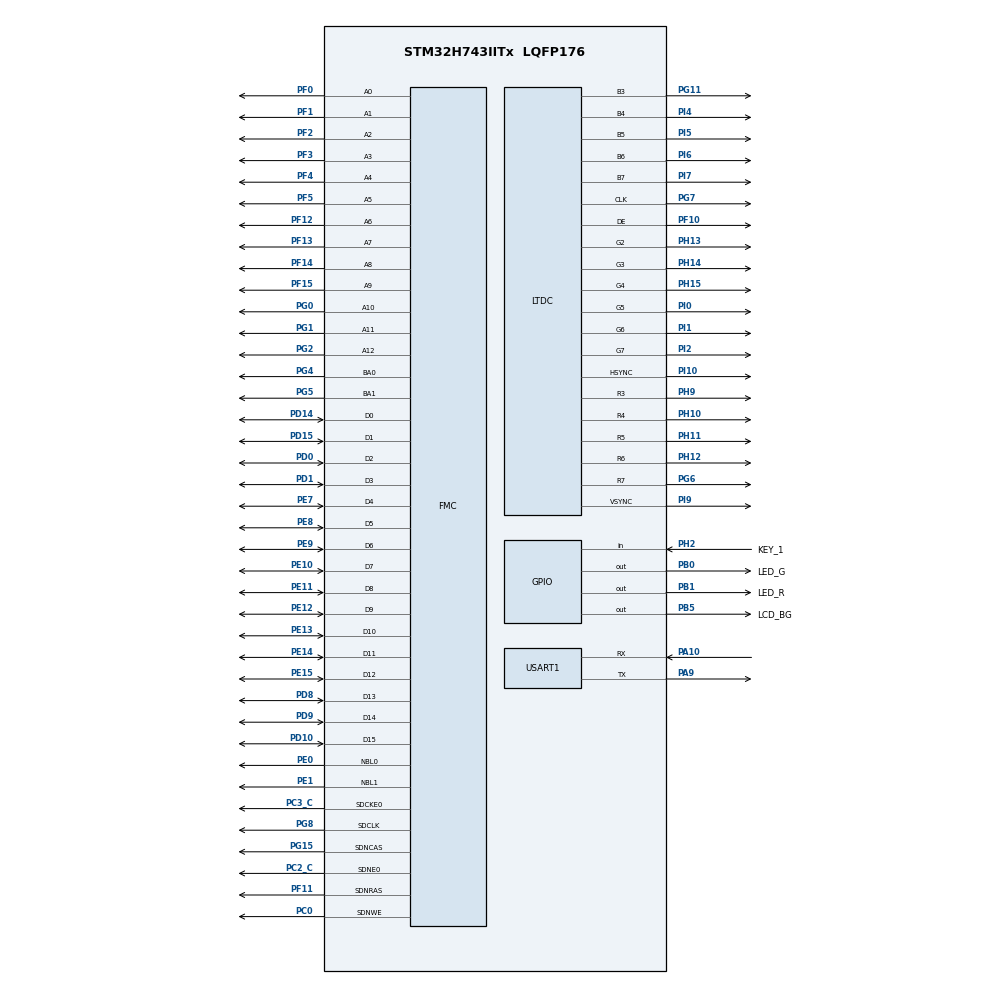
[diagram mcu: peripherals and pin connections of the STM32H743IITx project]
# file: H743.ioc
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CORTEX_M7.CPU_DCache=Enabled
CORTEX_M7.CPU_ICache=Enabled
DMA2D.ColorMode=DMA2D_OUTPUT_RGB565
FMC.CASLatency1=FMC_SDRAM_CAS_LATENCY_2
FMC.ColumnBitsNumber1=FMC_SDRAM_COLUMN_BITS_NUM_9
FMC.ExitSelfRefreshDelay1=8
FMC.LoadToActiveDelay1=2
FMC.RCDDelay1=2
FMC.RPDelay1=2
FMC.RPDelay2=2
FMC.ReadBurst1=FMC_SDRAM_RBURST_ENABLE
FMC.ReadBurst2=FMC_SDRAM_RBURST_ENABLE
FMC.ReadPipeDelay1=FMC_SDRAM_RPIPE_DELAY_0
FMC.RowCycleDelay1=7
FMC.RowCycleDelay2=7
FMC.SDClockPeriod1=FMC_SDRAM_CLOCK_PERIOD_2
FMC.SDClockPeriod2=FMC_SDRAM_CLOCK_PERIOD_2
FMC.SelfRefreshTime1=7
FMC.WriteRecoveryTime1=5
FREERTOS.BinarySemaphores01=ScreenFlushSemaphore,Dynamic,NULL,Depleted
FREERTOS.Queues01=LEDQueue,16,LEDMessage*,0,Dynamic,NULL,NULL;CommandQueue,16,uint8_t,0,Dynamic,NULL,NULL
FREERTOS.Tasks01=UITask,24,2048,StartUITask,As weak,NULL,Dynamic,NULL,NULL;KeyScanTask,40,128,StartKeyScanTask,As external,NULL,Dynamic,NULL,NULL;LEDTask,24,128,StartLEDTask,As external,NULL,Dynamic,NULL,NULL
FREERTOS.configCHECK_FOR_STACK_OVERFLOW=2
FREERTOS.configGENERATE_RUN_TIME_STATS=1
FREERTOS.configRECORD_STACK_HIGH_ADDRESS=1
FREERTOS.configTOTAL_HEAP_SIZE=32768
FREERTOS.configUSE_STATS_FORMATTING_FUNCTIONS=1
FREERTOS.configUSE_TICK_HOOK=1
LTDC.ActiveH=480
LTDC.ActiveW=800
LTDC.Alpha0_L0=255
LTDC.Alpha_L0=255
LTDC.Blue_L0=255
LTDC.FBStartAdress_L0=0xC0000000
LTDC.HBP=46
LTDC.HFP=210
LTDC.HSync=1
LTDC.ImageHeight_L0=480
LTDC.ImageWidth_L0=800
LTDC.Layers=0
LTDC.PixelFormat_L0=LTDC_PIXEL_FORMAT_RGB565
LTDC.VBP=23
LTDC.VFP=22
LTDC.VSync=1
LTDC.WindowX1_L0=800
LTDC.WindowY1_L0=480
Mcu.Family=STM32H7
Mcu.Name=STM32H743IITx
Mcu.Package=LQFP176
NVIC.DMA2D_IRQn=true\:7\:0\:true\:false\:true\:true\:true\:true\:true
NVIC.LTDC_IRQn=true\:7\:0\:true\:false\:true\:true\:true\:true\:true
NVIC.PriorityGroup=NVIC_PRIORITYGROUP_4
NVIC.TIM6_DAC_IRQn=true\:0\:0\:true\:false\:true\:false\:true\:true\:true
NVIC.TimeBase=TIM6_DAC_IRQn
NVIC.TimeBaseIP=TIM6
NVIC.USART1_IRQn=true\:5\:0\:false\:false\:true\:true\:true\:true\:true
PA10.GPIO_Speed=GPIO_SPEED_FREQ_VERY_HIGH
PA10.Mode=Asynchronous
PA10.Signal=USART1_RX
PA13\ (JTMS/SWDIO).Mode=Serial_Wire
PA13\ (JTMS/SWDIO).Signal=DEBUG_JTMS-SWDIO
PA14\ (JTCK/SWCLK).Mode=Serial_Wire
PA14\ (JTCK/SWCLK).Signal=DEBUG_JTCK-SWCLK
PA9.GPIO_Speed=GPIO_SPEED_FREQ_VERY_HIGH
PA9.Mode=Asynchronous
PA9.Signal=USART1_TX
PB0.GPIO_Label=LED_G
PB0.GPIO_Speed=GPIO_SPEED_FREQ_VERY_HIGH
PB0.Signal=GPIO_Output
PB1.GPIO_Label=LED_R
PB1.GPIO_Speed=GPIO_SPEED_FREQ_VERY_HIGH
PB1.Signal=GPIO_Output
PB5.GPIO_Label=LCD_BG
PB5.GPIO_ModeDefaultOutputPP=GPIO_MODE_OUTPUT_PP
PB5.GPIO_Speed=GPIO_SPEED_FREQ_VERY_HIGH
PB5.PinState=GPIO_PIN_SET
PB5.Signal=GPIO_Output
PC0.Signal=FMC_SDNWE
PC14-OSC32_IN\ (OSC32_IN).Mode=LSE-External-Oscillator
PC14-OSC32_IN\ (OSC32_IN).Signal=RCC_OSC32_IN
PC15-OSC32_OUT\ (OSC32_OUT).Mode=LSE-External-Oscillator
PC15-OSC32_OUT\ (OSC32_OUT).Signal=RCC_OSC32_OUT
PC2_C.Mode=SdramChipSelect1_1
PC2_C.Signal=FMC_SDNE0
PC3_C.Mode=SdramChipSelect1_1
PC3_C.Signal=FMC_SDCKE0
PD0.Signal=FMC_D2_DA2
PD1.Signal=FMC_D3_DA3
PD10.Signal=FMC_D15_DA15
PD14.Signal=FMC_D0_DA0
PD15.Signal=FMC_D1_DA1
PD8.Signal=FMC_D13_DA13
PD9.Signal=FMC_D14_DA14
PE0.Signal=FMC_NBL0
PE1.Signal=FMC_NBL1
PE10.Signal=FMC_D7_DA7
PE11.Signal=FMC_D8_DA8
PE12.Signal=FMC_D9_DA9
PE13.Signal=FMC_D10_DA10
PE14.Signal=FMC_D11_DA11
PE15.Signal=FMC_D12_DA12
PE7.Signal=FMC_D4_DA4
PE8.Signal=FMC_D5_DA5
PE9.Signal=FMC_D6_DA6
PF0.Signal=FMC_A0
PF1.Signal=FMC_A1
PF10.GPIO_Speed=GPIO_SPEED_FREQ_VERY_HIGH
PF10.Mode=RGB565
PF10.Signal=LTDC_DE
PF11.Signal=FMC_SDNRAS
PF12.Signal=FMC_A6
PF13.Signal=FMC_A7
PF14.Signal=FMC_A8
PF15.Signal=FMC_A9
PF2.Signal=FMC_A2
PF3.Signal=FMC_A3
PF4.Signal=FMC_A4
PF5.Signal=FMC_A5
PG0.Signal=FMC_A10
PG1.Signal=FMC_A11
PG11.GPIO_Speed=GPIO_SPEED_FREQ_VERY_HIGH
PG11.Mode=RGB565
PG11.Signal=LTDC_B3
PG15.Signal=FMC_SDNCAS
PG2.Signal=FMC_A12
PG4.Signal=FMC_A14_BA0
PG5.Signal=FMC_A15_BA1
PG6.GPIO_Speed=GPIO_SPEED_FREQ_VERY_HIGH
PG6.Mode=RGB565
PG6.Signal=LTDC_R7
PG7.GPIO_Speed=GPIO_SPEED_FREQ_VERY_HIGH
PG7.Mode=RGB565
PG7.Signal=LTDC_CLK
PG8.Signal=FMC_SDCLK
PH0-OSC_IN\ (PH0).Mode=HSE-External-Oscillator
PH0-OSC_IN\ (PH0).Signal=RCC_OSC_IN
PH1-OSC_OUT\ (PH1).Mode=HSE-External-Oscillator
PH1-OSC_OUT\ (PH1).Signal=RCC_OSC_OUT
PH10.GPIO_Speed=GPIO_SPEED_FREQ_VERY_HIGH
PH10.Mode=RGB565
PH10.Signal=LTDC_R4
PH11.GPIO_Speed=GPIO_SPEED_FREQ_VERY_HIGH
PH11.Mode=RGB565
PH11.Signal=LTDC_R5
PH12.GPIO_Speed=GPIO_SPEED_FREQ_VERY_HIGH
PH12.Mode=RGB565
PH12.Signal=LTDC_R6
PH13.GPIO_Speed=GPIO_SPEED_FREQ_VERY_HIGH
PH13.Mode=RGB565
PH13.Signal=LTDC_G2
PH14.GPIO_Speed=GPIO_SPEED_FREQ_VERY_HIGH
PH14.Mode=RGB565
PH14.Signal=LTDC_G3
PH15.GPIO_Speed=GPIO_SPEED_FREQ_VERY_HIGH
PH15.Mode=RGB565
PH15.Signal=LTDC_G4
PH2.GPIO_Label=KEY_1
PH2.GPIO_PuPd=GPIO_PULLUP
PH2.Signal=GPIO_Input
PH9.GPIO_Speed=GPIO_SPEED_FREQ_VERY_HIGH
PH9.Mode=RGB565
PH9.Signal=LTDC_R3
PI0.GPIO_Speed=GPIO_SPEED_FREQ_VERY_HIGH
PI0.Mode=RGB565
PI0.Signal=LTDC_G5
PI1.GPIO_Speed=GPIO_SPEED_FREQ_VERY_HIGH
PI1.Mode=RGB565
PI1.Signal=LTDC_G6
PI10.GPIO_Speed=GPIO_SPEED_FREQ_VERY_HIGH
PI10.Mode=RGB565
PI10.Signal=LTDC_HSYNC
PI2.GPIO_Speed=GPIO_SPEED_FREQ_VERY_HIGH
PI2.Mode=RGB565
PI2.Signal=LTDC_G7
PI4.GPIO_Speed=GPIO_SPEED_FREQ_VERY_HIGH
PI4.Mode=RGB565
PI4.Signal=LTDC_B4
PI5.GPIO_Speed=GPIO_SPEED_FREQ_VERY_HIGH
PI5.Mode=RGB565
PI5.Signal=LTDC_B5
PI6.GPIO_Speed=GPIO_SPEED_FREQ_VERY_HIGH
PI6.Mode=RGB565
PI6.Signal=LTDC_B6
PI7.GPIO_Speed=GPIO_SPEED_FREQ_VERY_HIGH
PI7.Mode=RGB565
PI7.Signal=LTDC_B7
PI9.GPIO_Speed=GPIO_SPEED_FREQ_VERY_HIGH
PI9.Mode=RGB565
PI9.Signal=LTDC_VSYNC
ProjectManager.HeapSize=0x2000
ProjectManager.StackSize=0x2000
ProjectManager.TargetToolchain=CMake
RCC.ADCFreq_Value=110000000
RCC.APB1Freq_Value=120000000
RCC.APB2Freq_Value=120000000
RCC.APB3Freq_Value=120000000
RCC.APB4Freq_Value=120000000
RCC.CortexFreq_Value=480000000
RCC.D1PPRE=RCC_APB3_DIV2
RCC.D2PPRE1=RCC_APB1_DIV2
RCC.D2PPRE2=RCC_APB2_DIV2
RCC.D3PPRE=RCC_APB4_DIV2
RCC.DIVM1=5
RCC.DIVM2=25
RCC.DIVM3=25
RCC.DIVN1=192
RCC.DIVN2=220
RCC.DIVN3=300
RCC.DIVR2=1
RCC.DIVR3=9
RCC.FMCCLockSelection=RCC_FMCCLKSOURCE_PLL2
RCC.HCLKFreq_Value=240000000
RCC.HPRE=RCC_HCLK_DIV2
RCC.PLLFRACN=0
RCC.PLLSourceVirtual=RCC_PLLSOURCE_HSE
RCC.SYSCLKFreq_VALUE=480000000
RCC.SYSCLKSource=RCC_SYSCLKSOURCE_PLLCLK
RCC.USBFreq_Value=480000000
SH.FMC_A0.0=FMC_A0,13b-sda1
SH.FMC_A1.0=FMC_A1,13b-sda1
SH.FMC_A10.0=FMC_A10,13b-sda1
SH.FMC_A11.0=FMC_A11,13b-sda1
SH.FMC_A12.0=FMC_A12,13b-sda1
SH.FMC_A14_BA0.0=FMC_BA0,FourSdramBanks1
SH.FMC_A15_BA1.0=FMC_BA1,FourSdramBanks1
SH.FMC_A2.0=FMC_A2,13b-sda1
SH.FMC_A3.0=FMC_A3,13b-sda1
SH.FMC_A4.0=FMC_A4,13b-sda1
SH.FMC_A5.0=FMC_A5,13b-sda1
SH.FMC_A6.0=FMC_A6,13b-sda1
SH.FMC_A7.0=FMC_A7,13b-sda1
SH.FMC_A8.0=FMC_A8,13b-sda1
SH.FMC_A9.0=FMC_A9,13b-sda1
SH.FMC_D0_DA0.0=FMC_D0,sd-16b-d1
SH.FMC_D10_DA10.0=FMC_D10,sd-16b-d1
SH.FMC_D11_DA11.0=FMC_D11,sd-16b-d1
SH.FMC_D12_DA12.0=FMC_D12,sd-16b-d1
SH.FMC_D13_DA13.0=FMC_D13,sd-16b-d1
SH.FMC_D14_DA14.0=FMC_D14,sd-16b-d1
SH.FMC_D15_DA15.0=FMC_D15,sd-16b-d1
SH.FMC_D1_DA1.0=FMC_D1,sd-16b-d1
SH.FMC_D2_DA2.0=FMC_D2,sd-16b-d1
SH.FMC_D3_DA3.0=FMC_D3,sd-16b-d1
SH.FMC_D4_DA4.0=FMC_D4,sd-16b-d1
SH.FMC_D5_DA5.0=FMC_D5,sd-16b-d1
SH.FMC_D6_DA6.0=FMC_D6,sd-16b-d1
SH.FMC_D7_DA7.0=FMC_D7,sd-16b-d1
SH.FMC_D8_DA8.0=FMC_D8,sd-16b-d1
SH.FMC_D9_DA9.0=FMC_D9,sd-16b-d1
SH.FMC_NBL0.0=FMC_NBL0,Sd2ByteEnable1
SH.FMC_NBL1.0=FMC_NBL1,Sd2ByteEnable1
SH.FMC_SDCLK.0=FMC_SDCLK,13b-sda1
SH.FMC_SDNCAS.0=FMC_SDNCAS,13b-sda1
SH.FMC_SDNRAS.0=FMC_SDNRAS,13b-sda1
SH.FMC_SDNWE.0=FMC_SDNWE,13b-sda1
USART1.VirtualMode-Asynchronous=VM_ASYNC
VP_DMA2D_VS_DMA2D.Mode=DMA2D_Activate
VP_FREERTOS_VS_CMSIS_V2.Mode=CMSIS_V2
VP_MEMORYMAP_VS_MEMORYMAP.Mode=CurAppReg
VP_SYS_VS_tim6.Mode=TIM6
board=custom

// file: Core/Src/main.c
/* USER CODE BEGIN Header */
/**
  ******************************************************************************
  * @file           : main.c
  * @brief          : Main program body
  ******************************************************************************
  * @attention
  *
  * Copyright (c) 2026 STMicroelectronics.
  * All rights reserved.
  *
  * This software is licensed under terms that can be found in the LICENSE file
  * in the root directory of this software component.
  * If no LICENSE file comes with this software, it is provided AS-IS.
  *
  ******************************************************************************
  */
/* USER CODE END Header */
#include "main.h"
#include "FreeRTOS.h"
#include "cmsis_os2.h"
#include "dma2d.h"
#include "ltdc.h"
#include "usart.h"
#include "gpio.h"
#include "fmc.h"

void SystemClock_Config(void);
void MX_FREERTOS_Init(void);

int main(void)
{

  /* Enable the CPU Cache */

  /* Enable I-Cache---------------------------------------------------------*/
  SCB_EnableICache();

  /* Enable D-Cache---------------------------------------------------------*/
  SCB_EnableDCache();

  /* MCU Configuration--------------------------------------------------------*/

  /* Reset of all peripherals, Initializes the Flash interface and the Systick. */
  HAL_Init();

  /* USER CODE BEGIN Init */
  SCB->CACR |= 1 << 2; /* 强制 D-Cache 透写模式 */
  /* USER CODE END Init */

  /* Configure the system clock */
  SystemClock_Config();

  /* Initialize all configured peripherals */
  MX_GPIO_Init();
  MX_LTDC_Init();
  MX_FMC_Init();
  MX_DMA2D_Init();
  MX_USART1_UART_Init();

  /* Init scheduler */
  osKernelInitialize();  /* Call init function for freertos objects (in cmsis_os2.c) */
  MX_FREERTOS_Init();

  /* Start scheduler */
  osKernelStart();

  /* We should never get here as control is now taken by the scheduler */

  /* Infinite loop */
  while (1) {

  }
}

void SystemClock_Config(void)
{
  RCC_OscInitTypeDef RCC_OscInitStruct = {0};
  RCC_ClkInitTypeDef RCC_ClkInitStruct = {0};

  /** Supply configuration update enable
  */
  HAL_PWREx_ConfigSupply(PWR_LDO_SUPPLY);

  /** Configure the main internal regulator output voltage
  */
  __HAL_PWR_VOLTAGESCALING_CONFIG(PWR_REGULATOR_VOLTAGE_SCALE0);

  while(!__HAL_PWR_GET_FLAG(PWR_FLAG_VOSRDY)) {}

  /** Initializes the RCC Oscillators according to the specified parameters
  * in the RCC_OscInitTypeDef structure.
  */
  RCC_OscInitStruct.OscillatorType = RCC_OSCILLATORTYPE_HSE;
  RCC_OscInitStruct.HSEState = RCC_HSE_ON;
  RCC_OscInitStruct.PLL.PLLState = RCC_PLL_ON;
  RCC_OscInitStruct.PLL.PLLSource = RCC_PLLSOURCE_HSE;
  RCC_OscInitStruct.PLL.PLLM = 5;
  RCC_OscInitStruct.PLL.PLLN = 192;
  RCC_OscInitStruct.PLL.PLLP = 2;
  RCC_OscInitStruct.PLL.PLLQ = 2;
  RCC_OscInitStruct.PLL.PLLR = 2;
  RCC_OscInitStruct.PLL.PLLRGE = RCC_PLL1VCIRANGE_2;
  RCC_OscInitStruct.PLL.PLLVCOSEL = RCC_PLL1VCOWIDE;
  RCC_OscInitStruct.PLL.PLLFRACN = 0;
  if (HAL_RCC_OscConfig(&RCC_OscInitStruct) != HAL_OK)
  {
    Error_Handler();
  }

  /** Initializes the CPU, AHB and APB buses clocks
  */
  RCC_ClkInitStruct.ClockType = RCC_CLOCKTYPE_HCLK|RCC_CLOCKTYPE_SYSCLK
                              |RCC_CLOCKTYPE_PCLK1|RCC_CLOCKTYPE_PCLK2
                              |RCC_CLOCKTYPE_D3PCLK1|RCC_CLOCKTYPE_D1PCLK1;
  RCC_ClkInitStruct.SYSCLKSource = RCC_SYSCLKSOURCE_PLLCLK;
  RCC_ClkInitStruct.SYSCLKDivider = RCC_SYSCLK_DIV1;
  RCC_ClkInitStruct.AHBCLKDivider = RCC_HCLK_DIV2;
  RCC_ClkInitStruct.APB3CLKDivider = RCC_APB3_DIV2;
  RCC_ClkInitStruct.APB1CLKDivider = RCC_APB1_DIV2;
  RCC_ClkInitStruct.APB2CLKDivider = RCC_APB2_DIV2;
  RCC_ClkInitStruct.APB4CLKDivider = RCC_APB4_DIV2;

  if (HAL_RCC_ClockConfig(&RCC_ClkInitStruct, FLASH_LATENCY_4) != HAL_OK)
  {
    Error_Handler();
  }
}

void HAL_TIM_PeriodElapsedCallback(TIM_HandleTypeDef *htim)
{
  if (htim->Instance == TIM6)
  {
    HAL_IncTick();
  }
}

void Error_Handler(void)
{
  __disable_irq();
  while (1) {
  }
}

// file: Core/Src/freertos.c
/* USER CODE BEGIN Header */
/**
  ******************************************************************************
  * File Name          : freertos.c
  * Description        : Code for freertos applications
  ******************************************************************************
  * @attention
  *
  * Copyright (c) 2026 STMicroelectronics.
  * All rights reserved.
  *
  * This software is licensed under terms that can be found in the LICENSE file
  * in the root directory of this software component.
  * If no LICENSE file comes with this software, it is provided AS-IS.
  *
  ******************************************************************************
  */
/* USER CODE END Header */

#include "FreeRTOS.h"
#include "task.h"
#include "main.h"
#include "FreeRTOS.h"
#include "cmsis_os2.h"

/* USER CODE BEGIN Includes */
#include <stdio.h>
#include <string.h>
#include "lvgl.h"
#include "stm32h7xx_hal.h"
#include "Tasks/Inc/LED.h"
/* USER CODE END Includes */

/* Definitions for UITask */
osThreadId_t UITaskHandle;
const osThreadAttr_t UITask_attributes = {
  .name = "UITask",
  .stack_size = 2048 * 4,
  .priority = (osPriority_t) osPriorityNormal,
};
/* Definitions for KeyScanTask */
osThreadId_t KeyScanTaskHandle;
const osThreadAttr_t KeyScanTask_attributes = {
  .name = "KeyScanTask",
  .stack_size = 128 * 4,
  .priority = (osPriority_t) osPriorityHigh,
};
/* Definitions for LEDTask */
osThreadId_t LEDTaskHandle;
const osThreadAttr_t LEDTask_attributes = {
  .name = "LEDTask",
  .stack_size = 128 * 4,
  .priority = (osPriority_t) osPriorityNormal,
};
/* Definitions for LEDQueue */
osMessageQueueId_t LEDQueueHandle;
const osMessageQueueAttr_t LEDQueue_attributes = {
  .name = "LEDQueue"
};
/* Definitions for CommandQueue */
osMessageQueueId_t CommandQueueHandle;
const osMessageQueueAttr_t CommandQueue_attributes = {
  .name = "CommandQueue"
};
/* Definitions for ScreenFlushSemaphore */
osSemaphoreId_t ScreenFlushSemaphoreHandle;
const osSemaphoreAttr_t ScreenFlushSemaphore_attributes = {
  .name = "ScreenFlushSemaphore"
};

void StartUITask(void *argument);
extern void StartKeyScanTask(void *argument);
extern void StartLEDTask(void *argument);

void MX_FREERTOS_Init(void); /* (MISRA C 2004 rule 8.1) */

/* Hook prototypes */
void configureTimerForRunTimeStats(void);
unsigned long getRunTimeCounterValue(void);
void vApplicationTickHook(void);
void vApplicationStackOverflowHook(xTaskHandle xTask, char *pcTaskName);

/* USER CODE BEGIN 1 */
/* Functions needed when configGENERATE_RUN_TIME_STATS is on */
__weak void configureTimerForRunTimeStats(void)
{
}

__weak unsigned long getRunTimeCounterValue(void)
{
  return 0;
}

/* USER CODE END 1 */

/* USER CODE BEGIN 3 */
void vApplicationTickHook(void)
{
  /* This function will be called by each tick interrupt if
  configUSE_TICK_HOOK is set to 1 in FreeRTOSConfig.h. User code can be
  added here, but the tick hook is called from an interrupt context, so
  code must not attempt to block, and only the interrupt safe FreeRTOS API
  functions can be used (those that end in FromISR()). */
  lv_tick_inc(1);
}

/* USER CODE END 3 */

/* USER CODE BEGIN 4 */
void vApplicationStackOverflowHook(xTaskHandle xTask, char *pcTaskName)
{
  /* Run time stack overflow checking is performed if
  configCHECK_FOR_STACK_OVERFLOW is defined to 1 or 2. This hook function is
  called if a stack overflow is detected. */
}

/* USER CODE END 4 */

void MX_FREERTOS_Init(void) {

  /* Create the semaphores(s) */
  /* creation of ScreenFlushSemaphore */
  ScreenFlushSemaphoreHandle = osSemaphoreNew(1, 0, &ScreenFlushSemaphore_attributes);

  /* Create the queue(s) */
  /* creation of LEDQueue */
  LEDQueueHandle = osMessageQueueNew (16, sizeof(LEDMessage*), &LEDQueue_attributes);

  /* creation of CommandQueue */
  CommandQueueHandle = osMessageQueueNew (16, sizeof(uint8_t), &CommandQueue_attributes);

  /* Create the thread(s) */
  /* creation of UITask */
  UITaskHandle = osThreadNew(StartUITask, NULL, &UITask_attributes);

  /* creation of KeyScanTask */
  KeyScanTaskHandle = osThreadNew(StartKeyScanTask, NULL, &KeyScanTask_attributes);

  /* creation of LEDTask */
  LEDTaskHandle = osThreadNew(StartLEDTask, NULL, &LEDTask_attributes);

}

__weak void StartUITask(void *argument)
{
}
